# CCG2 register map
File version: 1.0
CPU: CM0 r1p0, little endian, no MPU, no FPU, 2 interrupt priority bits
Registers are 32-bit, read-write, reset 0x0 unless marked. A register's access mark holds for its fields unless they carry their own. Offsets are from the block's base; [hi:lo] are bit positions; {n}, {i} and the like mark numbered series; 'fields as' and 'values as' point back to an identical list.

## SRSSLT
Base 0x40030000
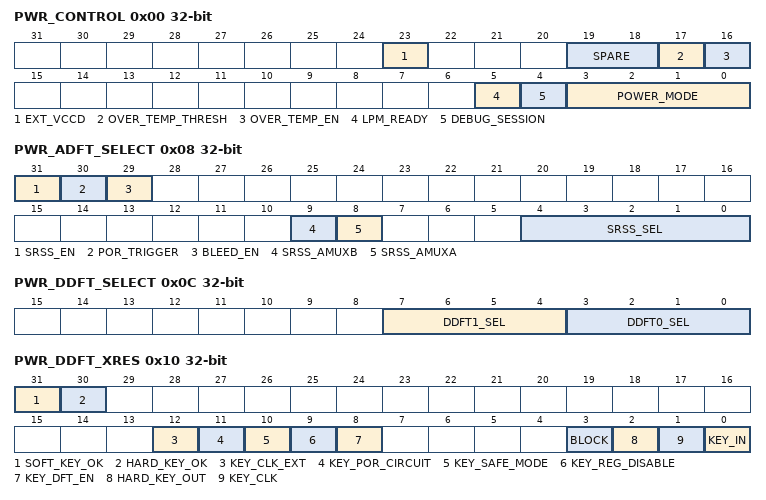
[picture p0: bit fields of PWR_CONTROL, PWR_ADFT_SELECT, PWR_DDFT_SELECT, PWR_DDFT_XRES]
0x00 PWR_CONTROL — Power Mode Control Controls the device power mode options and allows observation of current state.
  [23] EXT_VCCD — Always write 0 except as noted below. PSoC4-S0 and Streetfighter CapSense products may set this bit if Vccd is provided externally (on Vccd pin). Setting this bit turns off the active regulator and will lead to system reset (BOD) unless both Vddd and Vccd pins are supplied externally. This register bit only resets for XRES, POR, or a detected BOD.
  [19:18] SPARE ro — Spare AHB readback bits that are hooked to PWR_PWRSYS_TRIM1.SPARE_TRIM[1:0] through spare logic equivalent to bitwise inversion. Engineering only.
  [17] OVER_TEMP_THRESH — Over-temperature threshold. 0: TEMP_HIGH condition occurs between 120C and 125C. 1: TEMP_HIGH condition occurs between 60C and 75C (used for testing).
  [16] OVER_TEMP_EN — Enables the die over temperature sensor. Must be enabled when using the TEMP_HIGH interrupt.
  [5] LPM_READY ro — Indicates whether the low power mode regulator is ready to enter DEEPSLEEP mode. 0: If DEEPSLEEP mode is requested, device will enter SLEEP mode. When low power regulators are ready, device will automatically enter the originally requested mode. 1: Normal operation. DEEPSLEEP works as described.
  [4] DEBUG_SESSION ro — Indicates whether a debug session is active (CDBGPWRUPREQ signal is 1)
    0=NO_SESSION; 1=SESSION_ACTIVE
  [3:0] POWER_MODE ro — Current power mode of the device. Note that this field cannot be read in all power modes on actual silicon.
    0=RESET; 1=ACTIVE; 2=SLEEP; 3=DEEP_SLEEP
0x04 PWR_KEY_DELAY reset 0xF8 — Power System Key&Delay Register
  [9:0] WAKEUP_HOLDOFF — Delay to wait for references to settle on wakeup from deepsleep. BOD is ignored and system does not resume until this delay expires. Note that the same delay on POR is hard-coded. The default assumes the output of the predivider is 48MHz + 3%. Firmware may scale this setting according to the fastest actual clock frequency that can occur when waking from DEEPSLEEP.
0x08 PWR_ADFT_SELECT — Power ADFT Mode Selection Register Controls System Resources ADFT mode settings and observability. Writes to this register are ignored and settings in this register have no effect unless the part is in a XRES key selected DfT mode. Entire register is engineering only. Note that PWR_DDFT_XRES can be used to enter an XRES key if XRES key sequence is not desired.
  [31] SRSS_EN — Enables/disables the system resources ADFT observability. Disable this bit before changing the ADFT selection. This prevents glitches and transients from affecting the references. There is no internal hardware break-before-make.
  [30] POR_TRIGGER — Setting this bit will trigger a rst_por_hv_n reset from the s8srsslta. The system will go through POR reset.
  [29] BLEED_EN — When set enables bleeder cells on various switched power nets to accelerate discharge during low power mode testing.
  [9] SRSS_AMUXB — Connect amuxbusb to selected ADFT signal. 0: do not connect 1: connect
  [8] SRSS_AMUXA — Connect amuxbusa to selected ADFT signal. 0: do not connect 1: connect
  [4:0] SRSS_SEL — Selects the current or voltage source from SRSS-Lite that needs to be observed. Currents are only available through amuxbusa. Voltages are available though both amuxbusa and amuxbusb (Kelvin connections).
    {v}=IREF{v} (v=0..19); 20=IREF_MAIN; 21=IREF_LOCAL; 22=IREF_SPARE1; 23=IREF_IMO_REG; 24=VCCD; 25=VBG_1P25; 26=VREF_1P2; 27=DSREF_0P74; 28=VSSD; 29=VREG_1P55; 30=VSSQ; 31=IREF_ALL
0x0C PWR_DDFT_SELECT — Power DDFT Mode Selection Register Selects the signal sources output to the DDFT outputs of the power subsystem. Entire register is engineering only.
  [7:4] DDFT1_SEL — Select signal for power DDFT output #1
    0=WAKEUP; 1=AWAKE; 2=ACT_POWER_EN; 3=ACT_POWER_UP; 4=ACT_POWER_GOOD; 5=ACT_REF_VALID; 6=ACT_REG_VALID; 7=ACT_COMP_OUT; 8=ACT_TEMP_HIGH; 9=DPSLP_COMP_OUT; 10=DPSLP_POWER_UP; 11=AWAKE_DELAYED; 12=LPM_READY; 13=SLEEPHOLDACK_N; 14=GND; 15=PWR
  [3:0] DDFT0_SEL — Select signal for power DDFT output #0
    0=WAKEUP; 1=AWAKE; 2=ACT_POWER_EN; 3=ACT_POWER_UP; 4=ACT_POWER_GOOD; 5=ACT_REF_EN; 6=ACT_COMP_EN; 7=DPSLP_REF_EN; 8=DPSLP_REG_EN; 9=DPSLP_COMP_EN; 10=OVER_TEMP_EN; 11=SLEEPHOLDREQ_N; 12=ADFT_BUF_EN; 13=ATPG_OBSERVE; 14=GND; 15=PWR
0x10 PWR_DDFT_XRES — XRES DfT Key observer logic test register This register is used to test the XRES TestMode key logic. It allows a test routine (firmware or ATE driven) to stimulate the key listener and observe its functionality. Extreme case must be taken in these tests, since they will result in actual test mode entry. For example, shifting in a scan mode key, will transition the system into scan mode immediately. Note that test_scan_mode is not observable in this register for that reason.
  [31] SOFT_KEY_OK ro — Indicates that the 125-bit key observer has observed the correct key
  [30] HARD_KEY_OK ro — Indicates that the 32-bit shift register has observed the correct key
  [12] KEY_CLK_EXT ro — Hooked up to test_key_clk_ext
  [11] KEY_POR_CIRCUIT ro — Hooked up to test_key_por_circuit
  [10] KEY_SAFE_MODE ro — Hooked up to test_key_safe_mode
  [9] KEY_REG_DISABLE ro — Hooked up to test_key_reg_disable
  [8] KEY_DFT_EN ro — Hooked up to test_key_dft_en
  [3] BLOCK — Set this to 1 to block all test_key_* signals (blocks both logic side effects and bits in this register)
  [2] HARD_KEY_OUT ro — Output of the 32-bit hard key shift register
  [1] KEY_CLK — Tied to the XRES DfT key observation shift register clock.
  [0] KEY_IN — Tied to the XRES DfT key observation shift register input.
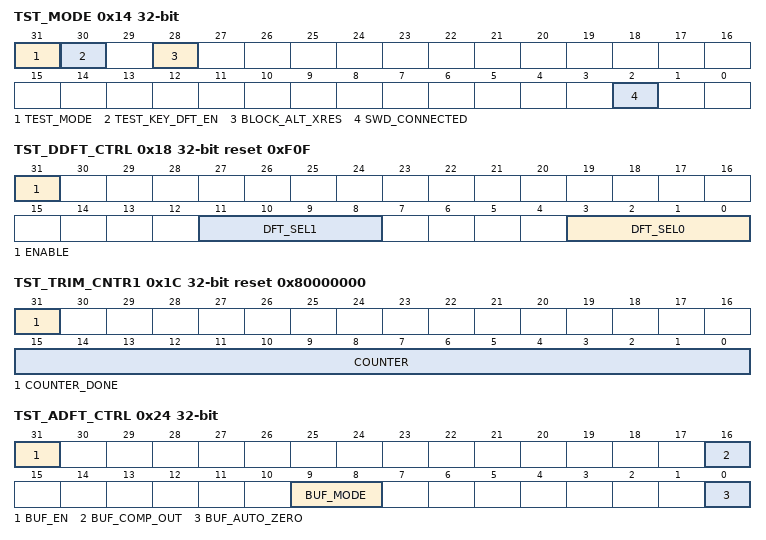
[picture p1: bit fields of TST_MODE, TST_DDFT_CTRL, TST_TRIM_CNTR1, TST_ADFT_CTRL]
0x14 TST_MODE — Test Mode Control Register Controls primary test mode. This is a single bit that can be written directly from the ATE/Programmer in any protection mode. It's main function is to signal to the Boot ROM that normal firmware execution is not to commence after boot is complete. Instead the Boot ROM will enter a wait loop for system commands.
  [31] TEST_MODE — 0: Normal operation mode 1: Test mode (any test mode) Setting this bit will prevent BootROM from yielding execution to Flash image.
  [30] TEST_KEY_DFT_EN ro — This bit is set when a XRES test mode key is shifted in. It is the value of the test_key_dft_en signal. When this bit is set, the BootROM will not yield execution to the FLASH image (same function as setting TEST_MODE bit below).
  [28] BLOCK_ALT_XRES — Relevant only for parts that have the alternate XRES mechanism of overloading a GPIO pin temporarily as alternate XRES during test. When set, this bit blocks the alternate XRES function, such that the pin can be used for normal I/O or for ddft/adft observation. See SAS Part-V and Part-IX for details. This register bit only resets for XRES, POR, or a detected BOD.
  [2] SWD_CONNECTED ro — 0: SWD not active 1: SWD activated (Line Reset & Connect sequence passed) (Note: this bit replaces TST_CTRL.SWD_CONNECTED and is present in all M0S8 products except TSG4)
0x18 TST_DDFT_CTRL reset 0xF0F — Digital DFT Control Register Controls system level DDFT observability muxes and comparators.
  [31] ENABLE — 1: Enables DDFT functionality. Connects output of DDFT mux to designated DDFT pin.
  [11:8] DFT_SEL1 — Select signal for DDFT output #1
    {v}=SRC{v} (v=0..7); 8=CLK0; 9=CLK1; 10=PWR0; 11=PWR1; 12=RES0; 13=RES1; 14=ADFT_COMP; 15=VSS
  [3:0] DFT_SEL0 — Select signal for DDFT output #0
    values as DFT_SEL1
0x1C TST_TRIM_CNTR1 reset 0x80000000 — IMO trim down-counter and status (clk_sys)
  [31] COUNTER_DONE ro — Status bit indicating that TRIM_CNTR1.COUNTER==0 and TRIM_CNT2.COUNTER stopped counting up
  [15:0] COUNTER — Down-counter clocked on clk_sys. By writing non-zero value to this counter TRIM_CNTR2.COUNTER clears and counts up. TRIM_CNTR1.COUNTER counts down until TRIM_CNTR1.COUNTER==0
0x20 TST_TRIM_CNTR2 — IMO trim up-counter (ddft)
  [15:0] COUNTER ro — Up-counter clocked on Clock DDFT output #1. When TRIM_CNTR1.COUNT_DONE==1 counter stopped and can be read by SW
0x24 TST_ADFT_CTRL — ADFT buffer/comparator control register Controls System Resources ADFT mode settings and observability. Writes to this register are ignored and settings in this register have no effect unless the part is in a XRES key selected DfT mode. Entire register is engineering only. Note that PWR_DDFT_XRES can be used to enter an XRES key if XRES key sequence is not desired.
  [31] BUF_EN — Enables the functionality of the ADFT buffer/comparator
  [16] BUF_COMP_OUT ro — Output of the ADFT comparator, 0 if in analog voltage buffer mode. This bit is also observable as a DDFT signal (see PWR_DDFT_SELECT).
  [9:8] BUF_MODE — Selects the operating mode for the ADFT buffer/comparator: 0: Voltage buffer, input is amuxbusa, output is amuxbusb 1: Voltage buffer, input is amuxbusb, output is amuxbusa 2: Comparator, input+ is amuxbusa, input- is amuxbusb 3: Comparator, input+ is amuxbusb, input- is amuxbusa
  [0] BUF_AUTO_ZERO — The ADFT buffer/comparator has a common mode dependent offset that can be greatly reduced by using this register bit. After settling the input signal(s), toggle this bit high briefly to sample and componsate for the offset. The buffer/comparator output will be unreliable when this bit is set.
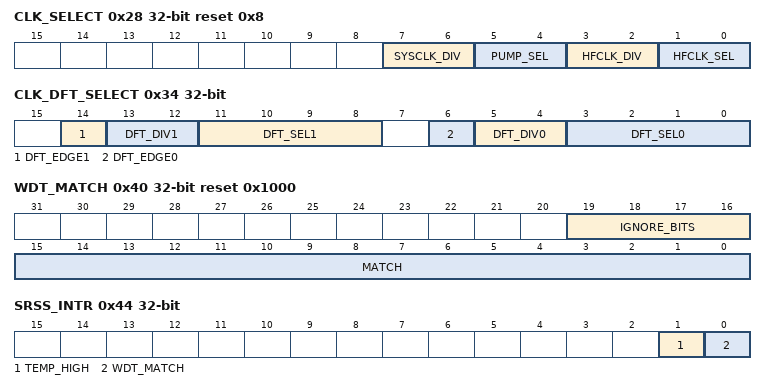
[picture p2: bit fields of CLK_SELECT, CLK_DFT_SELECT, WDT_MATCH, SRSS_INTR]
0x28 CLK_SELECT reset 0x8 — Clock Select Register Configures direction of all clock multiplexers and selectors. See Section 20.3 in SAS for details on clock network topology. See PAS for DSI signal connectivity list.
  [7:6] SYSCLK_DIV — Select clk_sys prescaler value.
    0=NO_DIV; 1=DIV_BY_2; 2=DIV_BY_4; 3=DIV_BY_8
  [5:4] PUMP_SEL — Selects clock source for charge pump clock. This clock is not guaranteed to be glitch free when changing any of its sources or settings.
    0=GND; 1=IMO; 2=HFCLK
  [3:2] HFCLK_DIV — Selects clk_hf predivider value.
    0=NO_DIV; 1=DIV_BY_2; 2=DIV_BY_4; 3=DIV_BY_8
  [1:0] HFCLK_SEL — Selects a source for clk_hf and dsi_in[0]. Note that not all products support all clock sources. Selecting a clock source that is not supported will result in undefined behavior.
    0=IMO; 1=EXTCLK; 2=ECO
0x2C CLK_ILO_CONFIG reset 0x80000000 — ILO Configuration Internal slow speed R/C oscillator (32kHz) configuration register. Note: writes to this register are ignored when WDT_DISABLE_KEY is not set to the magic value defined for it.
  [31] ENABLE — Master enable for ILO oscillator. This bit is hardware set whenever the WD_DISABLE_KEY is not set to the magic value.
0x30 CLK_IMO_CONFIG reset 0x80000000 — IMO Configuration Internal high speed R/C oscillator configuration register. Note that this oscillator comes up active on power up. The oscillator provides the primary system clock (HFCLK) on power up until firmware configures differently. This oscillator is also used before system start to count out power up delays. This is done in fast IMO (FIMO) mode that does not require any external references and runs at a fixed 12MHz.
  [31] ENABLE — Master enable for IMO oscillator. Clearing this bit will disable the IMO. Don't do this if the system is running off it.
0x34 CLK_DFT_SELECT — Clock DFT Mode Selection Register Selects which clock signals to bring out to to DFT pins. Two signals can be selected to enable comparison of clocks. Clocks can be divided down to deal with slower equipment and I/Os. See TST_DFT_SELECT for details on bringing these pins out. Entire register is engineering only.
  [14] DFT_EDGE1 — Edge sensitivity for in-line divider on output #1 (only relevant when DIV1>0).
    0=POSEDGE; 1=NEGEDGE
  [13:12] DFT_DIV1 — DFT Output Divide Down.
    0=NO_DIV; 1=DIV_BY_2; 2=DIV_BY_4; 3=DIV_BY_8
  [11:8] DFT_SEL1 — Select signal for DFT output #1
    0=NC; 1=ILO; 2=IMO; 3=ECO; 4=EXTCLK; 5=HFCLK; 6=LFCLK; 7=SYSCLK; 8=PUMPCLK; 9=SLPCTRLCLK
  [6] DFT_EDGE0 — Edge sensitivity for in-line divider on output #0 (only relevant when DIV0>0).
    0=POSEDGE; 1=NEGEDGE
  [5:4] DFT_DIV0 — DFT Output Divide Down.
    0=NO_DIV; 1=DIV_BY_2; 2=DIV_BY_4; 3=DIV_BY_8
  [3:0] DFT_SEL0 — Select signal for DFT output #0
    values as DFT_SEL1
0x38 WDT_DISABLE_KEY — Watchdog Disable Key Register This key can be used to disable the watchdog timer reset generation in applications that do not require absolute brown-out safety and do not want to deal with the hassle of feeding the watchdog regularly. Setting the key will also enable the CLK_ILO_CONFIG.ENABLE bit to be effective. It will not have any other effect, i.e. the WDT timer/interrupt functionality can still be used.
  [31:0] KEY — Disables WDT reset when equal to 0xACED8865. The WDT reset functions normally for any other setting.
0x3C WDT_COUNTER — Watchdog Counter Register Provides actual counter value for watchdog counter. Watchdog counter always counts up, is free-running and is clocked using clk_lf.
  [15:0] COUNTER ro — Current value of WDT Counter
0x40 WDT_MATCH reset 0x1000 — Watchdog Match Register Firmware provided match value that is compared against WDT_COUNTER. The expectation is that firmware modifies this register after each match as part of the WDT interrupt service routine.
  [19:16] IGNORE_BITS — The number of MSB bits of the watchdog timer that are NOT checked against MATCH. This value provides control over the time-to-reset of the watchdog (which happens after 3 successive matches). Note that certain products may enforce a minimum value for this register through design time configuration.
  [15:0] MATCH — Match value for Watchdog counter. Every time WDT_COUNTER reaches MATCH an interrupt is generated. Two unserviced interrupts will lead to a system reset (i.e. at the third match).
0x44 SRSS_INTR — SRSS Interrupt Register The intent is that this register is cleared for every WDT interrupt under all circumstances, including when the system is in DeepSleep.
  [1] TEMP_HIGH write-1-clears — Regulator over-temp interrupt. This interrupt can occur when a short circuit exists on the vccd pin or when extreme loads are applied on IO-cells causing the die to overheat. Firmware is encourage to shutdown all IO cells and then go to DeepSleep mode when this interrupt occurs if protection against such conditions is desired.
  [0] WDT_MATCH write-1-clears — WDT Interrupt Request. This bit is set each time WDT_COUNTR==WDT_MATCH. Clearing this bit also feeds the watch dog. Missing 2 interrupts in a row will generate brown-out reset. Due to internal synchronization, it takes 2 SYSCLK cycles to update after a W1C.
0x48 SRSS_INTR_SET — SRSS Interrupt Set Register Can be used to set interrupts for firmware testing. Note that SET functionality is not available for WDT.
  [1] TEMP_HIGH write-1-sets — Writing 1 to this bit internally sets the overtemp interrupt. This can be observed by reading SRSS_INTR.TEMP_HIGH. This bit always reads back as zero.
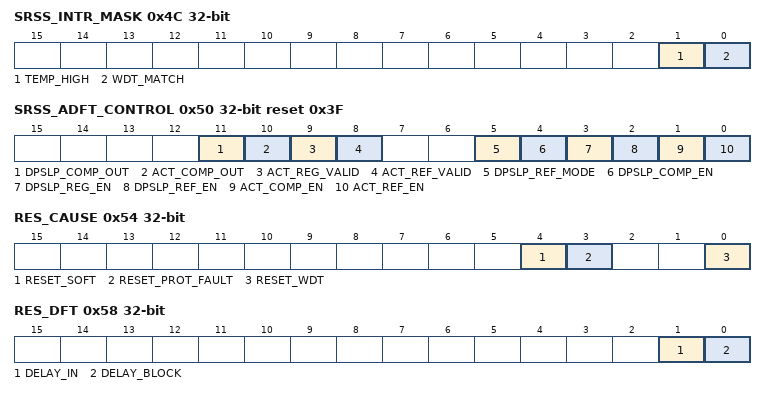
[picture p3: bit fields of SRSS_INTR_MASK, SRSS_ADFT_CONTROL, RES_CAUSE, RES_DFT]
0x4C SRSS_INTR_MASK — SRSS Interrupt Mask Register Controls whether interrupt is forwarded to CPU.
  [1] TEMP_HIGH — Masks REG_OVERTEMP interrupt
  [0] WDT_MATCH — Clearing this bit will not forward the interrupt to the CPU. It will not, however, disable the WDT reset generation on 2 missed interrupts.
0x50 SRSS_ADFT_CONTROL reset 0x3F — SRSS ADFT control register This register can be used only when in a test mode entered through an XRES:DFT:* key. It provides direct control over and visibility of the SRSS power and reference circuits. Note that act_reg_en is controlled through PWR_CONTROL.EXT_VCCD. It is possible to cause behavior that is normally considered illegal, such as disabling a circuit without regard for dependencies. Engineering only. Note that PWR_DDFT_XRES can be used to enter an XRES key if XRES key sequence is not desired.
  [11] DPSLP_COMP_OUT ro — Indicates DeepSleep comparator is valid
  [10] ACT_COMP_OUT ro — Indicates Active comparator is valid
  [9] ACT_REG_VALID ro — Indicates Active regulator is regulating
  [8] ACT_REF_VALID ro — Indicates Active reference is valid
  [5] DPSLP_REF_MODE — Mode override for the DeepSleep reference. 0=DEEPSLEEP, 1=ACTIVE. Clearing this bit allows characterization of the DeepSleep reference during ACTIVE mode.
  [4] DPSLP_COMP_EN — Enables/disables the DeepSleep power comparator
  [3] DPSLP_REG_EN — Enables/disables the DeepSleep regulator
  [2] DPSLP_REF_EN — Enables/disables the DeepSleep reference
  [1] ACT_COMP_EN — Enables/disables the Active power comparator. Set CLK_SELECT.HFCLK_SEL=EXTCLK before disabling the comparator.
  [0] ACT_REF_EN — Enables/disables the Active reference. Set CLK_SELECT.HFCLK_SEL=EXTCLK before disabling the reference.
0x54 RES_CAUSE — Reset Cause Observation Register Indicates the cause for the latest reset(s) that occurred in the system. Note that resets due to power up and brown-outs below state retention voltages in regulated and unregulated domains cannot be distinguished from eachother. All bits in this register assert when the corresponding reset cause occurs and must be cleared by firmware. These bits are cleared by hardware only during XRES, POR or after a detected brown-out.
  [4] RESET_SOFT write-1-clears — Cortex-M0 requested a system reset through it's SYSRESETREQ. This can be done via a debugger probe or in firmware.
  [3] RESET_PROT_FAULT write-1-clears — A protection violation occurred that requires a RESET. This includes, but is not limited to, hitting a debug breakpoint while in Privileged Mode.
  [0] RESET_WDT write-1-clears — A WatchDog Timer reset has occurred since last power cycle.
0x58 RES_DFT — Reset DFT Register Controls the DFT options for the reset system. Writes to this register are ignored and settings in this register have no effect unless DFT is enabled through a XRES:DFT:* key (see SAS for details). Note that PWR_DDFT_XRES can be used to enter an XRES key if XRES key sequence is not desired.
  [1] DELAY_IN — When DELAY_BLOCK=1, this bit is connected to the input of the reset delay line. Both the input and output can be observed through the DDFT network to measure their timing relationship.
  [0] DELAY_BLOCK — Setting this bit will disconnect the output of the reset delay line from the reset system blocking soft resets from reaching the logic. Note: XRES/POR/BOD resets still have other effects, but this bit MUST be cleared before XRES or any other reset can be applied to the system after doing the delay line testing. When DELAY_BLOCK=1, reset DDFT output #0 is connected the input of the delay line and output #1 is connected to the output of the delay line.
0xF00 PWR_BG_TRIM1 reset 0x10 — Bandgap Trim Register Trim bits for Reference System. Entire register is engineering only.
  [5:0] REF_VTRIM — Trims the bandgap reference voltage output. Used to trim the VBG to the voltage where its temperature curvature is minimal. Bit [5] is unused within the bandgap block.
0xF04 PWR_BG_TRIM2 reset 0x1C — Bandgap Trim Register Trim bits for Reference System. Entire register is engineering only.
  [5:0] REF_ITRIM — Trims the bandgap reference current output. Used to trim the IBG to the voltage where its temperature curvature is minimal.
0xF08 CLK_IMO_SELECT — IMO Frequency Select Register Selects the operating frequency of the IMO
  [2:0] FREQ — Select operating frequency
    0=24_MHZ; 1=28_MHZ; 2=32_MHZ; 3=36_MHZ; 4=40_MHZ; 5=44_MHZ; 6=48_MHZ
0xF0C CLK_IMO_TRIM1 reset 0x80 — IMO Trim Register Trims IMO frequency to within datasheet accuracy. Must be applied
  [7:0] OFFSET — Frequency trim bits. These bits are determined at manufacturing time for each FREQ setting (IMO_TRIM2) and stored in SFLASH. This field is hardware updated during USB osclock mode. This field is mapped to the most significant bits of the IMO trim imo_clk_trim[10:3]. The step size of 1 LSB on this field is approximately 120 kHz.
0xF10 CLK_IMO_TRIM2 — IMO Trim Register IMO Trim Bits. Entire register is engineering only.
  [2:0] FSOFFSET — Frequency trim bits. These bits are not trimmed during manufacturing and kept at 0 under normal operation. This field is hardware updated during USB osclock mode. This field is mapped to the least significant bits of the IMO trim imo_clk_trim[2:0]. The step size of 1 LSB on this field is approximately 15 kHz.
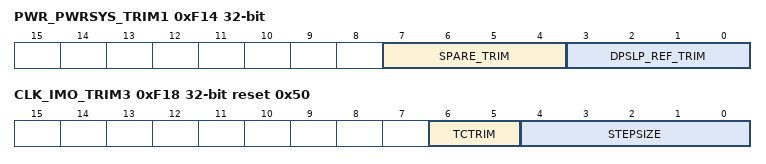
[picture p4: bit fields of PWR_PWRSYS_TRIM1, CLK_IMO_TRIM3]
0xF14 PWR_PWRSYS_TRIM1 — Power System Trim Register Power System Trim Bits. Entire register is engineering only.
  [7:4] SPARE_TRIM — Active-Reference temperature compensation trim (repurposed from spare bits). Bits [7:6] - trim the Active-Reference IREF temperature coefficient (TC). 00: TC = 0 (unchanged) 01: TC = +80ppm/C 10: TC = -80ppm/C 11: TC = -150ppm/C Bits [5:4] - trim the Active-Reference VREF temperature coefficient (TC). 00: TC = 0 (unchanged) 01: TC = -50ppm/C 10: TC = -80ppm/C 11: TC = +150ppm/C
  [3:0] DPSLP_REF_TRIM — Trims the DeepSleep reference that is used by the DeepSleep regulator and DeepSleep power comparator.
0xF18 CLK_IMO_TRIM3 reset 0x50 — IMO Trim Register IMO Trim Bits. Entire register is engineering only.
  [6:5] TCTRIM — IMO temperature compesation trim. These bits are determined at manufacturing time to adjust for temperature dependence. This bits are dependent on frequency and need to be changed using the Cypress provided frequency change algorithm.
  [4:0] STEPSIZE — IMO trim stepsize bits. These bits are determined at manufacturing time to adjust for process variation. They are used to tune the stepsize of the FSOFFSET and OFFSET trims.
